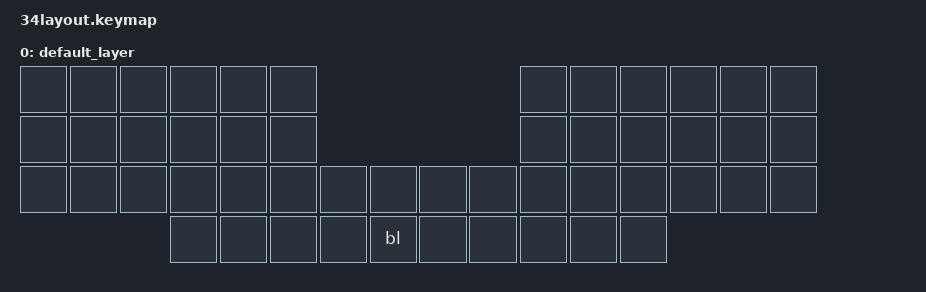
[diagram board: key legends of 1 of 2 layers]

/*
 * Copyright (c) 2020 The ZMK Contributors
 *
 * SPDX-License-Identifier: MIT
 */


/* THIS FILE WAS GENERATED!
 *
 * This file was generated automatically. You may or may not want to
 * edit it directly.
 */

#include <behaviors.dtsi>
#include <dt-bindings/zmk/backlight.h>

/ {
    keymap {
        compatible = "zmk,keymap";


        default_layer {
            bindings = <
  &none   &none   &none   &none   &none   &none                                   &none   &none   &none   &none   &none   &none
  &none   &none   &none   &none   &none   &none                                   &none   &none   &none   &none   &none   &none
  &none   &none   &none   &none   &none   &none   &none   &none   &none   &none   &none   &none   &none   &none   &none   &none
                          &none   &none   &none   &none     &bl   &none   &none   &none   &none   &none
            >;
        };

        layer_Layer__1 {
            bindings = <
 &trans  &trans  &trans  &trans  &trans  &trans                                  &trans  &trans  &trans  &trans  &trans  &trans
 &trans  &trans  &trans  &trans  &trans  &trans                                  &trans  &trans  &trans  &trans  &trans  &trans
 &trans  &trans  &trans  &trans  &trans
            >;
        };

    };
};
